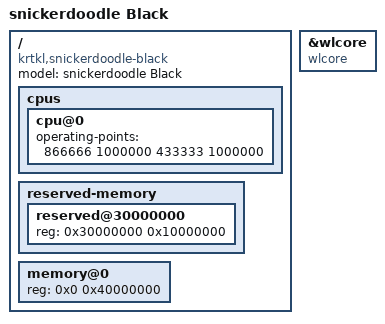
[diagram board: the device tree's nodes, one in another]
/**
 * Copyright (c) 2016 krtkl inc.
 *
 * snickerdoodle black base device tree source
 *
 * This program is free software; you can redistribute it and/or modify it
 * under the terms of the GNU General Public License version 2 as published by
 * the Free Software Foundation.
 */

/include/ "snickerdoodle.dtsi"
/ {
        model = "snickerdoodle Black";
        compatible = "krtkl,snickerdoodle-black", "krtkl,snickerdoodle", "xlnx,zynq-7000";

	cpus {
		cpu@0 {
			operating-points = <
				/* kHz	uV */
				866666	1000000
				433333	1000000
			>;
		};
	};

	reserved-memory {
		#address-cells = <1>;
		#size-cells = <1>;
		ranges;

		reserved@30000000 {
			reg = <0x30000000 0x10000000>;
		};
	};

	memory@0 {
		device_type = "memory";
		reg = <0x0 0x40000000>;
	};
};

&wlcore {
	compatible = "wlcore", "ti,wl1837";
};
